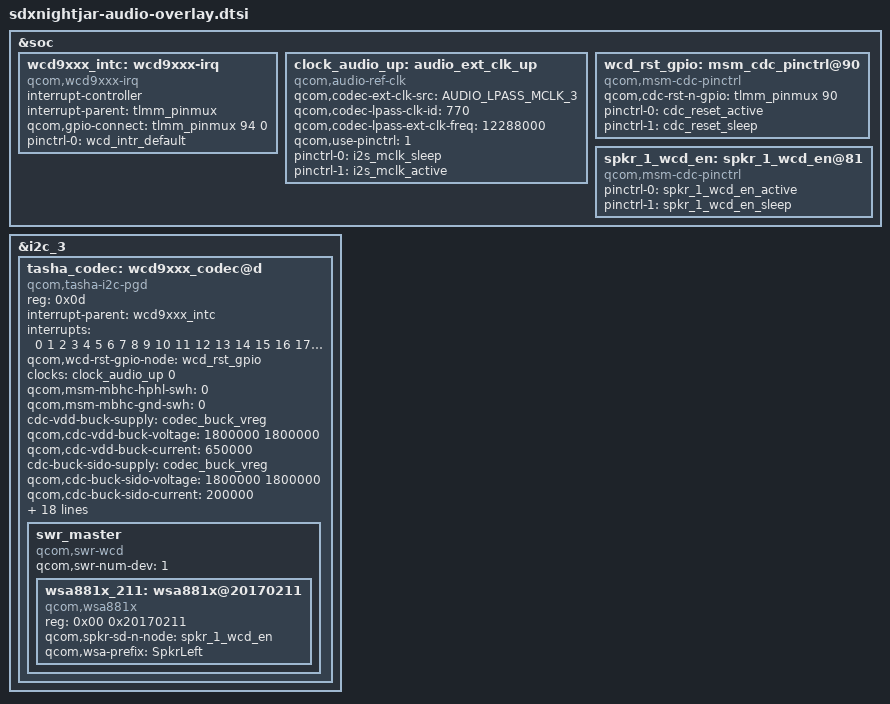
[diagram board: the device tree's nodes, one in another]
#include <dt-bindings/clock/qcom,audio-ext-clk.h>

&soc {
	wcd9xxx_intc: wcd9xxx-irq {
		status = "ok";
		compatible = "qcom,wcd9xxx-irq";
		interrupt-controller;
		#interrupt-cells = <1>;
		interrupt-parent = <&tlmm_pinmux>;
		qcom,gpio-connect = <&tlmm_pinmux 94 0>;
		pinctrl-names = "default";
		pinctrl-0 = <&wcd_intr_default>;
	};

	clock_audio_up: audio_ext_clk_up {
		compatible = "qcom,audio-ref-clk";
		qcom,codec-ext-clk-src = <AUDIO_LPASS_MCLK_3>;
		qcom,codec-lpass-clk-id = <770>;
		qcom,codec-lpass-ext-clk-freq = <12288000>;
		qcom,use-pinctrl = <1>;
		pinctrl-names = "sleep", "active";
		pinctrl-0 = <&i2s_mclk_sleep>;
		pinctrl-1 = <&i2s_mclk_active>;
		#clock-cells = <1>;
	};

	wcd_rst_gpio: msm_cdc_pinctrl@90 {
		compatible = "qcom,msm-cdc-pinctrl";
		qcom,cdc-rst-n-gpio = <&tlmm_pinmux 90 0>;
		pinctrl-names = "aud_active", "aud_sleep";
		pinctrl-0 = <&cdc_reset_active>;
		pinctrl-1 = <&cdc_reset_sleep>;
	};

	spkr_1_wcd_en: spkr_1_wcd_en@81 {
		compatible = "qcom,msm-cdc-pinctrl";
		pinctrl-names = "aud_active", "aud_sleep";
		pinctrl-0 = <&spkr_1_wcd_en_active>;
		pinctrl-1 = <&spkr_1_wcd_en_sleep>;
	};

};

&i2c_3 {
	status = "ok";
	tasha_codec: wcd9xxx_codec@d {
		compatible = "qcom,tasha-i2c-pgd";
		reg = <0x0d>;

		interrupt-parent = <&wcd9xxx_intc>;
		interrupts = <0 1 2 3 4 5 6 7 8 9 10 11 12 13 14 15 16
			      17 18 19 20 21 22 23 24 25 26 27 28 29
			      30>;

		qcom,wcd-rst-gpio-node = <&wcd_rst_gpio>;

		clock-names = "wcd_clk";
		clocks = <&clock_audio_up 0>;

		qcom,msm-mbhc-hphl-swh = <0>;
		qcom,msm-mbhc-gnd-swh = <0>;

		cdc-vdd-buck-supply = <&codec_buck_vreg>;
		qcom,cdc-vdd-buck-voltage = <1800000 1800000>;
		qcom,cdc-vdd-buck-current = <650000>;

		cdc-buck-sido-supply = <&codec_buck_vreg>;
		qcom,cdc-buck-sido-voltage = <1800000 1800000>;
		qcom,cdc-buck-sido-current = <200000>;

		cdc-vdd-tx-h-supply = <&pmd9650_l6>;
		qcom,cdc-vdd-tx-h-voltage = <1800000 1800000>;
		qcom,cdc-vdd-tx-h-current = <25000>;

		cdc-vdd-rx-h-supply = <&pmd9650_l6>;
		qcom,cdc-vdd-rx-h-voltage = <1800000 1800000>;
		qcom,cdc-vdd-rx-h-current = <25000>;

		cdc-vddpx-1-supply = <&pmd9650_l6>;
		qcom,cdc-vddpx-1-voltage = <1800000 1800000>;
		qcom,cdc-vddpx-1-current = <10000>;

		qcom,cdc-static-supplies = "cdc-vdd-buck",
					   "cdc-buck-sido",
					   "cdc-vdd-tx-h",
					   "cdc-vdd-rx-h",
					   "cdc-vddpx-1";

		qcom,cdc-micbias1-mv = <1800>;
		qcom,cdc-micbias2-mv = <1800>;
		qcom,cdc-micbias3-mv = <1800>;
		qcom,cdc-micbias4-mv = <1800>;
		qcom,cdc-mclk-clk-rate = <12288000>;
		qcom,cdc-dmic-sample-rate = <4800000>;

		swr_master {
			compatible = "qcom,swr-wcd";
			#address-cells = <2>;
			#size-cells = <0>;
			qcom,swr-num-dev = <1>;

			wsa881x_211: wsa881x@20170211 {
				compatible = "qcom,wsa881x";
				reg = <0x00 0x20170211>;
				qcom,spkr-sd-n-node = <&spkr_1_wcd_en>;
				qcom,wsa-prefix = "SpkrLeft";
			};
		};
	};
};
